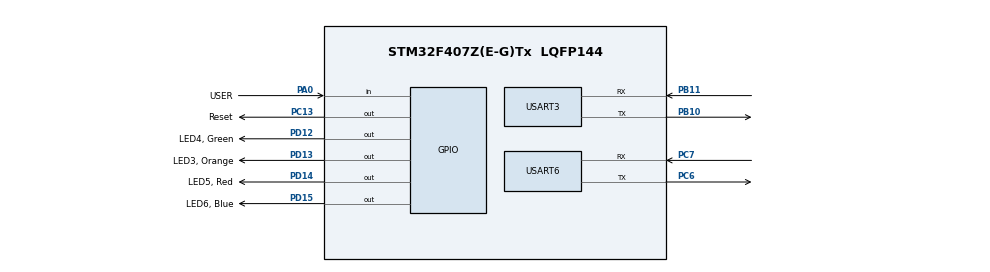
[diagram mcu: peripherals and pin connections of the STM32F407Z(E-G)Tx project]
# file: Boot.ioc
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Mcu.Family=STM32F4
PD12.GPIO_Label=LED4, Green
PH0-OSC_IN.Signal=RCC_OSC_IN
RCC.CortexFreq_Value=168000000
PD15.GPIO_Label=LED6, Blue
PB10.Mode=Asynchronous
PC13-ANTI_TAMP.GPIO_Label=Reset
PC6.Signal=USART6_TX
RCC.APB1CLKDivider=RCC_HCLK_DIV4
PB11.Signal=USART3_RX
PC13-ANTI_TAMP.PinState=GPIO_PIN_SET
RCC.SYSCLKSource=RCC_SYSCLKSOURCE_PLLCLK
ProjectManager.StackSize=0x800
PA0-WKUP.GPIO_Label=USER
PA0-WKUP.Signal=GPIO_Input
PD13.Signal=GPIO_Output
PB11.Mode=Asynchronous
ProjectManager.TargetToolchain=STM32CubeIDE
PC6.Mode=Asynchronous
RCC.HCLKFreq_Value=168000000
RCC.APB2TimFreq_Value=168000000
PC7.Signal=USART6_RX
RCC.LSE_VALUE=32768
RCC.AHBFreq_Value=168000000
PH0-OSC_IN.Mode=HSE-External-Oscillator
PB10.Signal=USART3_TX
RCC.HSE_VALUE=8000000
board=custom
PC13-ANTI_TAMP.Signal=GPIO_Output
RCC.VCOOutputFreq_Value=336000000
RCC.APB2Freq_Value=84000000
PH1-OSC_OUT.Signal=RCC_OSC_OUT
PD14.GPIO_Label=LED5, Red
Mcu.Name=STM32F407Z(E-G)Tx
PD14.Signal=GPIO_Output
PH1-OSC_OUT.Mode=HSE-External-Oscillator
RCC.48MHZClocksFreq_Value=48000000
RCC.SYSCLKFreq_VALUE=168000000
PD13.GPIO_Label=LED3, Orange
Mcu.Package=LQFP144
PB5.Signal=CAN2_RX
USART3.VirtualMode=VM_ASYNC
USART6.VirtualMode=VM_ASYNC
PD12.Signal=GPIO_Output
ProjectManager.HeapSize=0x200
RCC.HSI_VALUE=16000000
RCC.PLLQ=7
NVIC.PriorityGroup=NVIC_PRIORITYGROUP_4
RCC.APB2CLKDivider=RCC_HCLK_DIV2
RCC.PLLM=8
RCC.PLLN=168
RCC.APB1TimFreq_Value=84000000
PC7.Mode=Asynchronous
RCC.APB1Freq_Value=42000000
PD15.Signal=GPIO_Output

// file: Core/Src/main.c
/* USER CODE BEGIN Header */
/**
  ******************************************************************************
  * @file           : main.c
  * @brief          : Main program body
  ******************************************************************************
  * @attention
  *
  * <h2><center>&copy; Copyright (c) 2020 STMicroelectronics.
  * All rights reserved.</center></h2>
  *
  * This software component is licensed by ST under BSD 3-Clause license,
  * the "License"; You may not use this file except in compliance with the
  * License. You may obtain a copy of the License at:
  *                        opensource.org/licenses/BSD-3-Clause
  *
  ******************************************************************************
  */
/* USER CODE END Header */
#include "main.h"

/* USER CODE BEGIN Includes */
#include "app.h"
#include <stdio.h>
/* USER CODE END Includes */

UART_HandleTypeDef huart3;

/* USER CODE BEGIN PV */
extern const void* volatile _hal_vector_[];
extern void     Rs232TransmitByte(blt_int8u data);
/* USER CODE END PV */

void SystemClock_Config(void);
static void MX_GPIO_Init(void);
static void MX_USART6_UART_Init(void);
static void MX_USART3_UART_Init(void);

/* USER CODE BEGIN 0 */

/**
 * @brief	Send a char to debug port
 */
int __io_putchar(int ch)
{
	//__void__int8u Rs232TransmitByte1 =  (volatile void*) 0x08004315UL;
  Rs232TransmitByte(ch);
  //ITM_SendChar(ch);
  return(ch);
}

/* USER CODE END 0 */

int main(void)
{

  /* MCU Configuration--------------------------------------------------------*/

  /* Reset of all peripherals, Initializes the Flash interface and the Systick. */
  HAL_Init();

  /* Configure the system clock */
  SystemClock_Config();

  /* Initialize all configured peripherals */
  MX_GPIO_Init();
  MX_USART6_UART_Init();
  MX_USART3_UART_Init();
  /* USER CODE BEGIN 2 */
  /* Initialize the bootloader application. */
  AppInit();
  /* USER CODE END 2 */

  /* Infinite loop */
  /* USER CODE BEGIN WHILE */
  printf("... Main start ... \n");

  for (int i = 0; i < 4; i++)
  {
	  printf("hal_vector[%d] = 0x%8.8lX\n", i, (uint32_t)_hal_vector_[i]);
  }

  while (1)
  {
    /* Run the bootloader application. */
    AppTask();
    /* USER CODE END WHILE */

  }
}

void SystemClock_Config(void)
{
  LL_FLASH_SetLatency(LL_FLASH_LATENCY_5);
  while(LL_FLASH_GetLatency()!= LL_FLASH_LATENCY_5)
  {
  }
  LL_PWR_SetRegulVoltageScaling(LL_PWR_REGU_VOLTAGE_SCALE1);
  LL_RCC_HSI_SetCalibTrimming(16);
  LL_RCC_HSI_Enable();

   /* Wait till HSI is ready */
  while(LL_RCC_HSI_IsReady() != 1)
  {

  }
  LL_RCC_PLL_ConfigDomain_SYS(LL_RCC_PLLSOURCE_HSI, LL_RCC_PLLM_DIV_8, 168, LL_RCC_PLLP_DIV_2);
  LL_RCC_PLL_Enable();

   /* Wait till PLL is ready */
  while(LL_RCC_PLL_IsReady() != 1)
  {

  }
  LL_RCC_SetAHBPrescaler(LL_RCC_SYSCLK_DIV_1);
  LL_RCC_SetAPB1Prescaler(LL_RCC_APB1_DIV_4);
  LL_RCC_SetAPB2Prescaler(LL_RCC_APB2_DIV_2);
  LL_RCC_SetSysClkSource(LL_RCC_SYS_CLKSOURCE_PLL);

   /* Wait till System clock is ready */
  while(LL_RCC_GetSysClkSource() != LL_RCC_SYS_CLKSOURCE_STATUS_PLL)
  {

  }
  LL_SetSystemCoreClock(168000000);

   /* Update the time base */
  if (HAL_InitTick (TICK_INT_PRIORITY) != HAL_OK)
  {
    Error_Handler();
  }
}

static void MX_USART3_UART_Init(void)
{

  huart3.Instance = USART3;
  huart3.Init.BaudRate = 115200;
  huart3.Init.WordLength = UART_WORDLENGTH_8B;
  huart3.Init.StopBits = UART_STOPBITS_1;
  huart3.Init.Parity = UART_PARITY_NONE;
  huart3.Init.Mode = UART_MODE_TX_RX;
  huart3.Init.HwFlowCtl = UART_HWCONTROL_NONE;
  huart3.Init.OverSampling = UART_OVERSAMPLING_16;
  if (HAL_UART_Init(&huart3) != HAL_OK)
  {
    Error_Handler();
  }

}

static void MX_USART6_UART_Init(void)
{

  LL_USART_InitTypeDef USART_InitStruct = {0};

  LL_GPIO_InitTypeDef GPIO_InitStruct = {0};

  /* Peripheral clock enable */
  LL_APB2_GRP1_EnableClock(LL_APB2_GRP1_PERIPH_USART6);

  LL_AHB1_GRP1_EnableClock(LL_AHB1_GRP1_PERIPH_GPIOC);
  /**USART6 GPIO Configuration
  PC6   ------> USART6_TX
  PC7   ------> USART6_RX
  */
  GPIO_InitStruct.Pin = LL_GPIO_PIN_6|LL_GPIO_PIN_7;
  GPIO_InitStruct.Mode = LL_GPIO_MODE_ALTERNATE;
  GPIO_InitStruct.Speed = LL_GPIO_SPEED_FREQ_VERY_HIGH;
  GPIO_InitStruct.OutputType = LL_GPIO_OUTPUT_PUSHPULL;
  GPIO_InitStruct.Pull = LL_GPIO_PULL_NO;
  GPIO_InitStruct.Alternate = LL_GPIO_AF_8;
  LL_GPIO_Init(GPIOC, &GPIO_InitStruct);

  /* USER CODE BEGIN USART6_Init 1 */
  /* Note that the USART initialization that follows here is don't care. It is
   * reconfigured upon bootloader initialization with function Rs232Init().
   */
  /* USER CODE END USART6_Init 1 */
  USART_InitStruct.BaudRate = 115200;
  USART_InitStruct.DataWidth = LL_USART_DATAWIDTH_8B;
  USART_InitStruct.StopBits = LL_USART_STOPBITS_1;
  USART_InitStruct.Parity = LL_USART_PARITY_NONE;
  USART_InitStruct.TransferDirection = LL_USART_DIRECTION_TX_RX;
  USART_InitStruct.HardwareFlowControl = LL_USART_HWCONTROL_NONE;
  USART_InitStruct.OverSampling = LL_USART_OVERSAMPLING_16;
  LL_USART_Init(USART6, &USART_InitStruct);
  LL_USART_ConfigAsyncMode(USART6);
  LL_USART_Enable(USART6);

}

static void MX_GPIO_Init(void)
{
  LL_GPIO_InitTypeDef GPIO_InitStruct = {0};

  /* GPIO Ports Clock Enable */
  LL_AHB1_GRP1_EnableClock(LL_AHB1_GRP1_PERIPH_GPIOC);
  LL_AHB1_GRP1_EnableClock(LL_AHB1_GRP1_PERIPH_GPIOH);
  LL_AHB1_GRP1_EnableClock(LL_AHB1_GRP1_PERIPH_GPIOA);
  LL_AHB1_GRP1_EnableClock(LL_AHB1_GRP1_PERIPH_GPIOB);
  LL_AHB1_GRP1_EnableClock(LL_AHB1_GRP1_PERIPH_GPIOD);

  /**/
  LL_GPIO_SetOutputPin(Reset_GPIO_Port, Reset_Pin);

  /**/
  LL_GPIO_ResetOutputPin(GPIOD, LED4__Green_Pin|LED3__Orange_Pin|LED5__Red_Pin|LED6__Blue_Pin);

  /**/
  GPIO_InitStruct.Pin = Reset_Pin;
  GPIO_InitStruct.Mode = LL_GPIO_MODE_OUTPUT;
  GPIO_InitStruct.Speed = LL_GPIO_SPEED_FREQ_LOW;
  GPIO_InitStruct.OutputType = LL_GPIO_OUTPUT_PUSHPULL;
  GPIO_InitStruct.Pull = LL_GPIO_PULL_NO;
  LL_GPIO_Init(Reset_GPIO_Port, &GPIO_InitStruct);

  /**/
  GPIO_InitStruct.Pin = USER_Pin;
  GPIO_InitStruct.Mode = LL_GPIO_MODE_INPUT;
  GPIO_InitStruct.Pull = LL_GPIO_PULL_NO;
  LL_GPIO_Init(USER_GPIO_Port, &GPIO_InitStruct);

  /**/
  GPIO_InitStruct.Pin = LED4__Green_Pin|LED3__Orange_Pin|LED5__Red_Pin|LED6__Blue_Pin;
  GPIO_InitStruct.Mode = LL_GPIO_MODE_OUTPUT;
  GPIO_InitStruct.Speed = LL_GPIO_SPEED_FREQ_LOW;
  GPIO_InitStruct.OutputType = LL_GPIO_OUTPUT_PUSHPULL;
  GPIO_InitStruct.Pull = LL_GPIO_PULL_NO;
  LL_GPIO_Init(GPIOD, &GPIO_InitStruct);

  /**/
  GPIO_InitStruct.Pin = LL_GPIO_PIN_5;
  GPIO_InitStruct.Mode = LL_GPIO_MODE_ALTERNATE;
  GPIO_InitStruct.Speed = LL_GPIO_SPEED_FREQ_VERY_HIGH;
  GPIO_InitStruct.OutputType = LL_GPIO_OUTPUT_PUSHPULL;
  GPIO_InitStruct.Pull = LL_GPIO_PULL_NO;
  GPIO_InitStruct.Alternate = LL_GPIO_AF_9;
  LL_GPIO_Init(GPIOB, &GPIO_InitStruct);

}

void Error_Handler(void)
{
}

/************************ (C) COPYRIGHT STMicroelectronics *****END OF FILE****/
